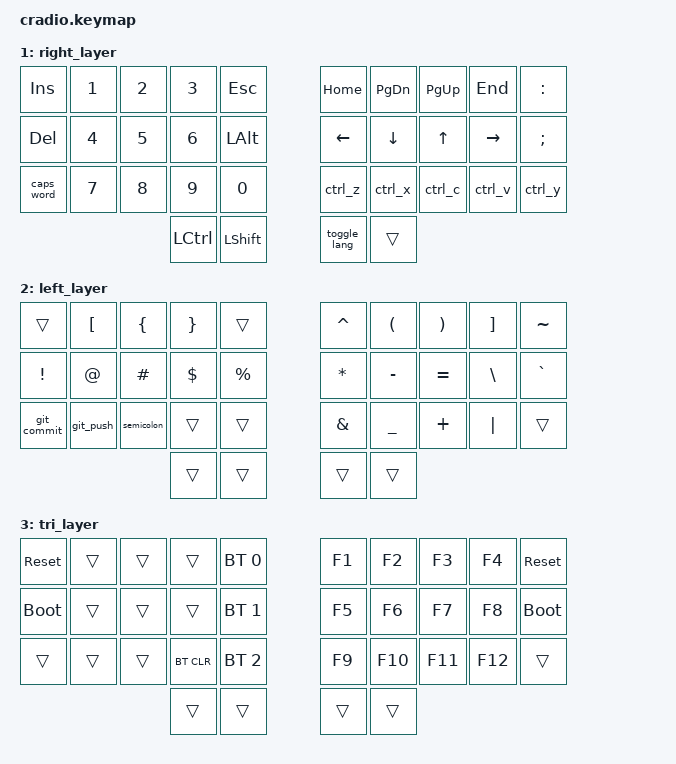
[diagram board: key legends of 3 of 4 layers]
// Copyright (c) 2022 The ZMK Contributors
// SPDX-License-Identifier: MIT

#include <behaviors.dtsi>
#include <dt-bindings/zmk/keys.h>
#include <dt-bindings/zmk/bt.h>

// Home row mods macro
#define HRML(k1,k2,k3,k4) &ht LSHFT k1  &ht LALT k2  &ht LCTRL k3  &ht LGUI k4
#define HRMR(k1,k2,k3,k4) &ht RGUI k1  &ht RCTRL k2  &ht RALT k3  &ht RSHFT k4

/ {
    behaviors {
        ht: hold_tap {
            compatible = "zmk,behavior-hold-tap";
            #binding-cells = <2>;
            flavor = "tap-preferred";
            tapping-term-ms = <220>;
            quick-tap-ms = <150>;
            require-prior-idle-ms = <100>;
            bindings = <&kp>, <&kp>;
        };
    };
	macros {
		toggle_lang: toggle_lang {
			compatible = "zmk,behavior-macro";
			#binding-cells = <0>;
			label = "Toggle Lang";
			bindings = <&kp LALT &kp LSHIFT>;
		};
		
		ctrl_z: ctrl_z {
			compatible = "zmk,behavior-macro";
			#binding-cells = <0>;
			label = "CTRL_Z";
			bindings = <&kp LC(Z)>;
		};

		ctrl_x: ctrl_x {
			compatible = "zmk,behavior-macro";
			#binding-cells = <0>;
			label = "CTRL_X";
			bindings = <&kp LC(X)>;
		};
		
		ctrl_c: ctrl_c {
			compatible = "zmk,behavior-macro";
			#binding-cells = <0>;
			label = "CTRL_C";
			bindings = <&kp LC(C)>;
		};

		ctrl_v: ctrl_v {
			compatible = "zmk,behavior-macro";
			#binding-cells = <0>;
			label = "CTRL_V";
			bindings = <&kp LC(V)>;
		};
		
		ctrl_y: ctrl_y {
			compatible = "zmk,behavior-macro";
			#binding-cells = <0>;
			label = "CTRL_V";
			bindings = <&kp LC(Y)>;
		};
		
		ctrl_bspc: ctrl_bspc {
			compatible = "zmk,behavior-macro";
			#binding-cells = <0>;
			label = "CTRL_BSPC";
			bindings = <&kp LC(BSPC)>;
		};

		git_commit: git_commit {
			compatible = "zmk,behavior-macro";
			#binding-cells = <0>;
			label = "GIT_COMMIT";
			bindings = <
				&kp G &kp I &kp T &kp SPC
				&kp C &kp O &kp M &kp M &kp I &kp T &kp SPC &kp M &kp S &kp G
				&macro_wait_time 100
			>;
		};

		git_push: git_push {
			compatible = "zmk,behavior-macro";
			#binding-cells = <0>;
			label = "GIT_PUSH";
			bindings = <
				&kp G &kp I &kp T &kp SPC
				&kp P &kp U &kp S &kp H
				&macro_wait_time 100
			>;
		};
		
		semicolon: semicolon {
			compatible = "zmk,behavior-macro";
			#binding-cells = <0>;
			label = "SEMICOLON";
			bindings = <
				&kp SEMI &kp SPC
			>;
		};
	};

    conditional_layers {
        compatible = "zmk,conditional-layers";
        tri_layer {
            if-layers = <1 2>;
            then-layer = <3>;
        };
    };

    keymap {
        compatible = "zmk,keymap";
        default_layer {
            bindings = <
        //╭──────────┬──────────┬──────────┬──────────┬──────────╮   ╭──────────┬──────────┬──────────┬──────────┬──────────╮
        //│  Q       │  W       │  E       │  R       │  T       │   │  Y       │  U       │  I       │  O       │  P       │
            &kp Q      &kp W      &kp E      &kp R      &kp T          &kp Y      &kp U      &kp I      &kp O      &kp P
        //├──────────┼──────────┼──────────┼──────────┼──────────┤   ├──────────┼──────────┼──────────┼──────────┼──────────┤
        //│  A       │  S       │  D       │  F       │  G       │   │  H       │  J       │  K       │  L       │ ' "      │
            HRML(A,        S,         D,         F)     &kp G          &kp H      HRMR(J,        K,         L,        SQT)
        //├──────────┼──────────┼──────────┼──────────┼──────────┤   ├──────────┼──────────┼──────────┼──────────┼──────────┤
        //│  Z       │  X       │  C       │  V       │  B       │   │  N       │  M       │ , <      │ . >      │ / ?      │
            &kp Z      &kp X      &kp C      &kp V      &kp B          &kp N      &kp M      &kp COMMA  &kp DOT    &kp FSLH
        //╰──────────┴──────────┴──────────┼──────────┼──────────┤   ├──────────┼──────────┼──────────┴──────────┴──────────╯
                                            &lt 2 TAB   &kp ENTER     &kp SPACE  &lt 1 BSPC
        //                                 ╰──────────┴──────────╯   ╰──────────┴──────────╯
            >;
        };

        right_layer {
            bindings = <
        //╭──────────┬──────────┬──────────┬──────────┬──────────╮   ╭──────────┬──────────┬──────────┬──────────┬──────────╮
        //│ INSERT   │  1       │  2       │  3       │          │   │ HOME     │ PAGE DN  │ PAGE UP  │ END      │  :       │
            &kp INS    &kp N1     &kp N2     &kp N3     &kp ESC        &kp HOME   &kp PG_DN  &kp PG_UP  &kp END    &kp COLON
        //├──────────┼──────────┼──────────┼──────────┼──────────┤   ├──────────┼──────────┼──────────┼──────────┼──────────┤
        //│ DELETE   │  4       │  5       │  6       │          │   │ LEFT     │ DOWN     │ UP       │ RIGHT    │  ;       │
            &kp DEL    &kp N4     &kp N5     &kp N6     &kp LALT       &kp LEFT   &kp DOWN   &kp UP   &kp RIGHT   &kp SEMI
        //├──────────┼──────────┼──────────┼──────────┼──────────┤   ├──────────┼──────────┼──────────┼──────────┼──────────┤
        //│ CAPS     │  7       │  8       │  9       │  0       │   │          │          │          │          │          │
           &caps_word  &kp N7     &kp N8     &kp N9     &kp N0         &ctrl_z    &ctrl_x   &ctrl_c     &ctrl_v   &ctrl_y
        //╰──────────┴──────────┴──────────┼──────────┼──────────┤   ├──────────┼──────────┼──────────┴──────────┴──────────╯
                                             &kp LCTRL  &kp LSHIFT    &toggle_lang     &trans
        //                                 ╰──────────┴──────────╯   ╰──────────┴──────────╯
            >;
        };
		
        left_layer {
            bindings = <
        //╭──────────┬──────────┬──────────┬──────────┬──────────╮   ╭──────────┬──────────┬──────────┬──────────┬──────────╮
        //│          │  [       │  {       │  }       │          │   │  ^       │  (       │  )       │  ]       │  ~       │
            &trans     &kp LBKT   &kp LBRC   &kp RBRC   &trans         &kp CARET  &kp LPAR   &kp RPAR   &kp RBKT   &kp TILDE
        //├──────────┼──────────┼──────────┼──────────┼──────────┤   ├──────────┼──────────┼──────────┼──────────┼──────────┤
        //│  !       │  @       │  #       │  $       │  %       │   │  *       │  -       │  =       │  \       │  `       │
            &kp EXCL   &kp AT     &kp HASH   &kp DLLR   &kp PRCNT      &kp ASTRK  &kp MINUS  &kp EQUAL  &kp BSLH   &kp GRAVE
        //├──────────┼──────────┼──────────┼──────────┼──────────┤   ├──────────┼──────────┼──────────┼──────────┼──────────┤
        //│          │          │          │          │          │   │  &       │  _       │  +       │  │       │          │
           &git_commit &git_push &semicolon   &trans     &trans         &kp AMPS   &kp UNDER  &kp PLUS   &kp PIPE   &trans
        //╰──────────┴──────────┴──────────┼──────────┼──────────┤   ├──────────┼──────────┼──────────┴──────────┴──────────╯
                                             &trans     &trans         &trans     &trans
        //                                 ╰──────────┴──────────╯   ╰──────────┴──────────╯
            >;
        };
		
        tri_layer {
            bindings = <
        //╭──────────┬──────────┬──────────┬──────────┬──────────╮   ╭──────────┬──────────┬──────────┬──────────┬──────────╮
        //│ RESET    │          │          │          │PROFILE 0 │   │          │          │          │          │  RESET   │
           &sys_reset  &trans     &trans     &trans    &bt BT_SEL 0    &kp F1   &kp F2     &kp F3     &kp F4   &sys_reset
        //├──────────┼──────────┼──────────┼──────────┼──────────┤   ├──────────┼──────────┼──────────┼──────────┼──────────┤
        //│BOOTLOADER│          │          │          │PROFILE 1 │   │          │          │          │          │BOOTLOADER│
          &bootloader  &trans     &trans     &trans    &bt BT_SEL 1    &kp F5     &kp F6     &kp F7     &kp F8    &bootloader
        //├──────────┼──────────┼──────────┼──────────┼──────────┤   ├──────────┼──────────┼──────────┼──────────┼──────────┤
        //│          │          │          │ CLEAR BT │PROFILE 2 │   │          │          │          │          │          │
            &trans     &trans     &trans    &bt BT_CLR &bt BT_SEL 2    &kp F9     &kp F10     &kp F11     &kp F12     &trans
        //╰──────────┴──────────┴──────────┼──────────┼──────────┤   ├──────────┼──────────┼──────────┴──────────┴──────────╯
                                             &trans     &trans         &trans     &trans
        //                                 ╰──────────┴──────────╯   ╰──────────┴──────────╯
            >;
        };
    };
};
